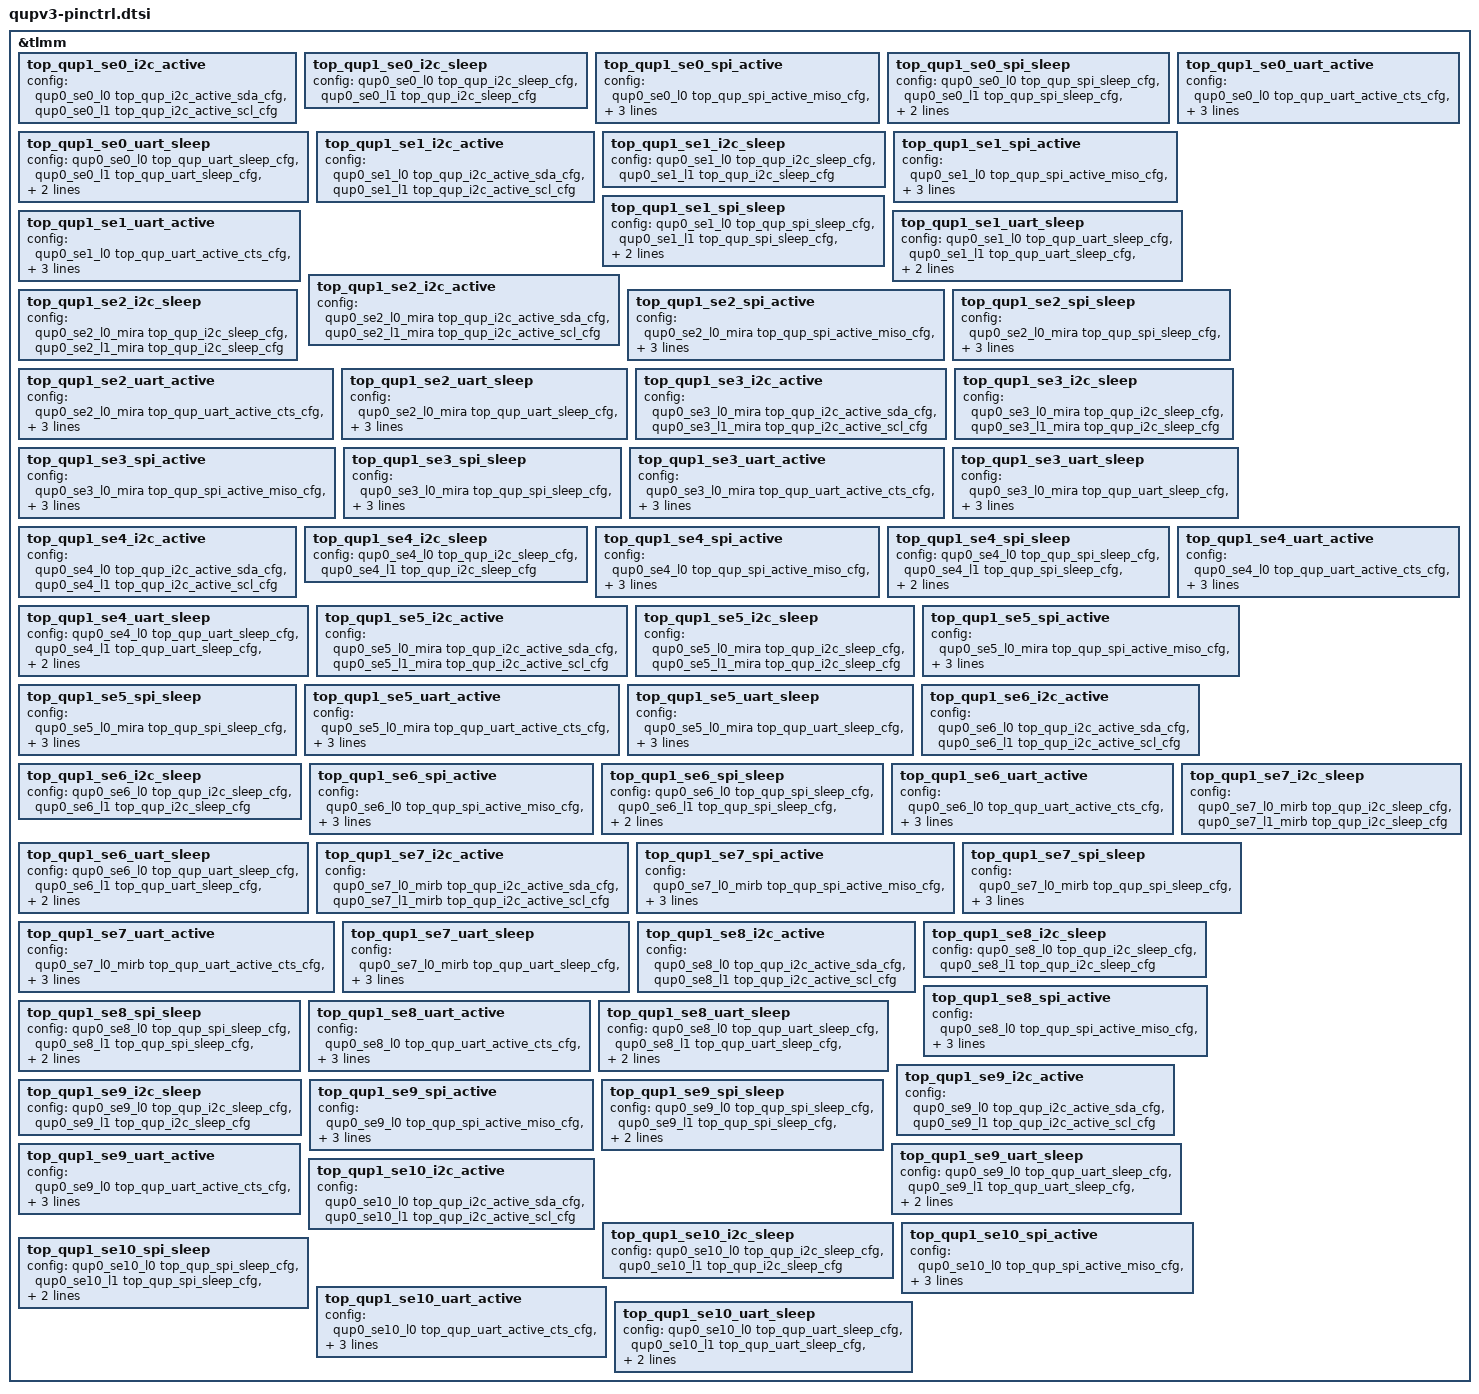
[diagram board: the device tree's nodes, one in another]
/**

This is the settings file for AspenA Top Qup pin control DTSI

Copyright (c) Qualcomm Technologies, Inc.
All Rights Reserved.
Confidential and Proprietary - Qualcomm Technologies, Inc.
*/
/*
===============================================================================
 
                               Edit History
 
$Header:
 
when       who     what, where, why
--------   ---     ------------------------------------------------------------
01/17/25           Initial revision
 
*/

#include "gpio-dt.h"

#define top_qup_spi_sleep_cfg             GPIO_CFG_BUSES(GPIO_INPUT,GPIO_KEEPER,GPIO_DRIVE_STRENGTH(200),0)

#define top_qup_spi_active_miso_cfg       GPIO_CFG_BUSES(GPIO_INPUT,GPIO_NO_PULL,GPIO_DRIVE_STRENGTH(600),0)
#define top_qup_spi_active_mosi_cfg       GPIO_CFG_BUSES(GPIO_OUTPUT,GPIO_NO_PULL,GPIO_DRIVE_STRENGTH(600),0)
#define top_qup_spi_active_clk_cfg        GPIO_CFG_BUSES(GPIO_OUTPUT,GPIO_NO_PULL,GPIO_DRIVE_STRENGTH(600),0)
#define top_qup_spi_active_cs_cfg         GPIO_CFG_BUSES(GPIO_OUTPUT,GPIO_NO_PULL,GPIO_DRIVE_STRENGTH(600),0)

#define top_qup_uart_active_cts_cfg       GPIO_CFG_BUSES(GPIO_INPUT,GPIO_NO_PULL,GPIO_DRIVE_STRENGTH(200),0)
#define top_qup_uart_active_rts_cfg       GPIO_CFG_BUSES(GPIO_OUTPUT,GPIO_NO_PULL,GPIO_DRIVE_STRENGTH(200),0)
#define top_qup_uart_active_tx_cfg        GPIO_CFG_BUSES(GPIO_OUTPUT,GPIO_NO_PULL,GPIO_DRIVE_STRENGTH(200),0)
#define top_qup_uart_active_rx_cfg        GPIO_CFG_BUSES(GPIO_INPUT,GPIO_NO_PULL,GPIO_DRIVE_STRENGTH(200),0)
#define top_qup_uart_sleep_cfg            GPIO_CFG_BUSES(GPIO_INPUT,GPIO_PULL_DOWN,GPIO_DRIVE_STRENGTH(200),0)

#define top_qup_i2c_active_sda_cfg        GPIO_CFG_BUSES(GPIO_OUTPUT,GPIO_PULL_UP,GPIO_DRIVE_STRENGTH(200),GPIO_STRONG_PULL)
#define top_qup_i2c_active_scl_cfg        GPIO_CFG_BUSES(GPIO_OUTPUT,GPIO_PULL_UP,GPIO_DRIVE_STRENGTH(200),GPIO_STRONG_PULL)
#define top_qup_i2c_sleep_cfg             GPIO_CFG_BUSES(GPIO_INPUT,GPIO_NO_PULL,GPIO_DRIVE_STRENGTH(200),GPIO_STRONG_PULL)


#define top_qup_i3c_active_sda_cfg        GPIO_CFG_BUSES(GPIO_OUTPUT,GPIO_PULL_UP,GPIO_DRIVE_STRENGTH(200),0)
#define top_qup_i3c_active_scl_cfg        GPIO_CFG_BUSES(GPIO_OUTPUT,GPIO_PULL_UP,GPIO_DRIVE_STRENGTH(200),0)
#define top_qup_i3c_sleep_cfg             GPIO_CFG_BUSES(GPIO_INPUT,GPIO_KEEPER,GPIO_DRIVE_STRENGTH(200),0)

&tlmm{
    /*top_qup1_se0_pinctrl*/
    top_qup1_se0_i2c_active: top_qup1_se0_i2c_active{
        config = <&qup0_se0_l0 top_qup_i2c_active_sda_cfg>,
                 <&qup0_se0_l1 top_qup_i2c_active_scl_cfg>;
    };

    top_qup1_se0_i2c_sleep: top_qup1_se0_i2c_sleep{
        config = <&qup0_se0_l0 top_qup_i2c_sleep_cfg>,
                 <&qup0_se0_l1 top_qup_i2c_sleep_cfg>;
    };

    top_qup1_se0_spi_active: top_qup1_se0_spi_active{
        config = <&qup0_se0_l0 top_qup_spi_active_miso_cfg>,
                 <&qup0_se0_l1 top_qup_spi_active_mosi_cfg>,
                 <&qup0_se0_l2 top_qup_spi_active_clk_cfg>,
                 <&qup0_se0_l3 top_qup_spi_active_cs_cfg>;
    };

    top_qup1_se0_spi_sleep: top_qup1_se0_spi_sleep{
        config = <&qup0_se0_l0 top_qup_spi_sleep_cfg>,
                 <&qup0_se0_l1 top_qup_spi_sleep_cfg>,
                 <&qup0_se0_l2 top_qup_spi_sleep_cfg>,
                 <&qup0_se0_l3 top_qup_spi_sleep_cfg>;
    };

    top_qup1_se0_uart_active: top_qup1_se0_uart_active{
        config = <&qup0_se0_l0 top_qup_uart_active_cts_cfg>,
                 <&qup0_se0_l1 top_qup_uart_active_rts_cfg>,
                 <&qup0_se0_l2 top_qup_uart_active_tx_cfg>,
                 <&qup0_se0_l3 top_qup_uart_active_rx_cfg>;
    };

    top_qup1_se0_uart_sleep: top_qup1_se0_uart_sleep{
        config = <&qup0_se0_l0 top_qup_uart_sleep_cfg>,
                 <&qup0_se0_l1 top_qup_uart_sleep_cfg>,
                 <&qup0_se0_l2 top_qup_uart_sleep_cfg>,
                 <&qup0_se0_l3 top_qup_uart_sleep_cfg>;
    };

    /*top_qup1_se1_pinctrl*/
    top_qup1_se1_i2c_active: top_qup1_se1_i2c_active{
        config = <&qup0_se1_l0 top_qup_i2c_active_sda_cfg>,
                 <&qup0_se1_l1 top_qup_i2c_active_scl_cfg>;
    };

    top_qup1_se1_i2c_sleep: top_qup1_se1_i2c_sleep{
        config = <&qup0_se1_l0 top_qup_i2c_sleep_cfg>,
                 <&qup0_se1_l1 top_qup_i2c_sleep_cfg>;
    };

    top_qup1_se1_spi_active: top_qup1_se1_spi_active{
        config = <&qup0_se1_l0 top_qup_spi_active_miso_cfg>,
                 <&qup0_se1_l1 top_qup_spi_active_mosi_cfg>,
                 <&qup0_se1_l2 top_qup_spi_active_clk_cfg>,
                 <&qup0_se1_l3 top_qup_spi_active_cs_cfg>;
    };

    top_qup1_se1_spi_sleep: top_qup1_se1_spi_sleep{
        config = <&qup0_se1_l0 top_qup_spi_sleep_cfg>,
                 <&qup0_se1_l1 top_qup_spi_sleep_cfg>,
                 <&qup0_se1_l2 top_qup_spi_sleep_cfg>,
                 <&qup0_se1_l3 top_qup_spi_sleep_cfg>;
    };

    top_qup1_se1_uart_active: top_qup1_se1_uart_active{
        config = <&qup0_se1_l0 top_qup_uart_active_cts_cfg>,
                 <&qup0_se1_l1 top_qup_uart_active_rts_cfg>,
                 <&qup0_se1_l2 top_qup_uart_active_tx_cfg>,
                 <&qup0_se1_l3 top_qup_uart_active_rx_cfg>;
    };

    top_qup1_se1_uart_sleep: top_qup1_se1_uart_sleep{
        config = <&qup0_se1_l0 top_qup_uart_sleep_cfg>,
                 <&qup0_se1_l1 top_qup_uart_sleep_cfg>,
                 <&qup0_se1_l2 top_qup_uart_sleep_cfg>,
                 <&qup0_se1_l3 top_qup_uart_sleep_cfg>;
    };

    /*top_qup1_se2_pinctrl*/
    top_qup1_se2_i2c_active: top_qup1_se2_i2c_active{
        config = <&qup0_se2_l0_mira top_qup_i2c_active_sda_cfg>,
                 <&qup0_se2_l1_mira top_qup_i2c_active_scl_cfg>;
    };

    top_qup1_se2_i2c_sleep: top_qup1_se2_i2c_sleep{
        config = <&qup0_se2_l0_mira top_qup_i2c_sleep_cfg>,
                 <&qup0_se2_l1_mira top_qup_i2c_sleep_cfg>;
    };

    top_qup1_se2_spi_active: top_qup1_se2_spi_active{
        config = <&qup0_se2_l0_mira top_qup_spi_active_miso_cfg>,
                 <&qup0_se2_l1_mira top_qup_spi_active_mosi_cfg>,
                 <&qup0_se2_l2_mira top_qup_spi_active_clk_cfg>,
                 <&qup0_se2_l3_mira top_qup_spi_active_cs_cfg>;
    };

    top_qup1_se2_spi_sleep: top_qup1_se2_spi_sleep{
        config = <&qup0_se2_l0_mira top_qup_spi_sleep_cfg>,
                 <&qup0_se2_l1_mira top_qup_spi_sleep_cfg>,
                 <&qup0_se2_l2_mira top_qup_spi_sleep_cfg>,
                 <&qup0_se2_l3_mira top_qup_spi_sleep_cfg>;
    };

    top_qup1_se2_uart_active: top_qup1_se2_uart_active{
        config = <&qup0_se2_l0_mira top_qup_uart_active_cts_cfg>,
                 <&qup0_se2_l1_mira top_qup_uart_active_rts_cfg>,
                 <&qup0_se2_l2_mira top_qup_uart_active_tx_cfg>,
                 <&qup0_se2_l3_mira top_qup_uart_active_rx_cfg>;
    };

    top_qup1_se2_uart_sleep: top_qup1_se2_uart_sleep{
        config = <&qup0_se2_l0_mira top_qup_uart_sleep_cfg>,
                 <&qup0_se2_l1_mira top_qup_uart_sleep_cfg>,
                 <&qup0_se2_l2_mira top_qup_uart_sleep_cfg>,
                 <&qup0_se2_l3_mira top_qup_uart_sleep_cfg>;
    };

    /*top_qup1_se3_pinctrl*/
    top_qup1_se3_i2c_active: top_qup1_se3_i2c_active{
        config = <&qup0_se3_l0_mira top_qup_i2c_active_sda_cfg>,
                 <&qup0_se3_l1_mira top_qup_i2c_active_scl_cfg>;
    };

    top_qup1_se3_i2c_sleep: top_qup1_se3_i2c_sleep{
        config = <&qup0_se3_l0_mira top_qup_i2c_sleep_cfg>,
                 <&qup0_se3_l1_mira top_qup_i2c_sleep_cfg>;
    };

    top_qup1_se3_spi_active: top_qup1_se3_spi_active{
        config = <&qup0_se3_l0_mira top_qup_spi_active_miso_cfg>,
                 <&qup0_se3_l1_mira top_qup_spi_active_mosi_cfg>,
                 <&qup0_se3_l2_mira top_qup_spi_active_clk_cfg>,
                 <&qup0_se3_l3_mira top_qup_spi_active_cs_cfg>;
    };

    top_qup1_se3_spi_sleep: top_qup1_se3_spi_sleep{
        config = <&qup0_se3_l0_mira top_qup_spi_sleep_cfg>,
                 <&qup0_se3_l1_mira top_qup_spi_sleep_cfg>,
                 <&qup0_se3_l2_mira top_qup_spi_sleep_cfg>,
                 <&qup0_se3_l3_mira top_qup_spi_sleep_cfg>;
    };

    top_qup1_se3_uart_active: top_qup1_se3_uart_active{
        config = <&qup0_se3_l0_mira top_qup_uart_active_cts_cfg>,
                 <&qup0_se3_l1_mira top_qup_uart_active_rts_cfg>,
                 <&qup0_se3_l2_mira top_qup_uart_active_tx_cfg>,
                 <&qup0_se3_l3_mira top_qup_uart_active_rx_cfg>;
    };

    top_qup1_se3_uart_sleep: top_qup1_se3_uart_sleep{
        config = <&qup0_se3_l0_mira top_qup_uart_sleep_cfg>,
                 <&qup0_se3_l1_mira top_qup_uart_sleep_cfg>,
                 <&qup0_se3_l2_mira top_qup_uart_sleep_cfg>,
                 <&qup0_se3_l3_mira top_qup_uart_sleep_cfg>;
    };

    /*top_qup1_se4_pinctrl*/
    top_qup1_se4_i2c_active: top_qup1_se4_i2c_active{
        config = <&qup0_se4_l0 top_qup_i2c_active_sda_cfg>,
                 <&qup0_se4_l1 top_qup_i2c_active_scl_cfg>;
    };

    top_qup1_se4_i2c_sleep: top_qup1_se4_i2c_sleep{
        config = <&qup0_se4_l0 top_qup_i2c_sleep_cfg>,
                 <&qup0_se4_l1 top_qup_i2c_sleep_cfg>;
    };

    top_qup1_se4_spi_active: top_qup1_se4_spi_active{
        config = <&qup0_se4_l0 top_qup_spi_active_miso_cfg>,
                 <&qup0_se4_l1 top_qup_spi_active_mosi_cfg>,
                 <&qup0_se4_l2 top_qup_spi_active_clk_cfg>,
                 <&qup0_se4_l3 top_qup_spi_active_cs_cfg>;
    };

    top_qup1_se4_spi_sleep: top_qup1_se4_spi_sleep{
        config = <&qup0_se4_l0 top_qup_spi_sleep_cfg>,
                 <&qup0_se4_l1 top_qup_spi_sleep_cfg>,
                 <&qup0_se4_l2 top_qup_spi_sleep_cfg>,
                 <&qup0_se4_l3 top_qup_spi_sleep_cfg>;
    };

    top_qup1_se4_uart_active: top_qup1_se4_uart_active{
        config = <&qup0_se4_l0 top_qup_uart_active_cts_cfg>,
                 <&qup0_se4_l1 top_qup_uart_active_rts_cfg>,
                 <&qup0_se4_l2 top_qup_uart_active_tx_cfg>,
                 <&qup0_se4_l3 top_qup_uart_active_rx_cfg>;
    };

    top_qup1_se4_uart_sleep: top_qup1_se4_uart_sleep{
        config = <&qup0_se4_l0 top_qup_uart_sleep_cfg>,
                 <&qup0_se4_l1 top_qup_uart_sleep_cfg>,
                 <&qup0_se4_l2 top_qup_uart_sleep_cfg>,
                 <&qup0_se4_l3 top_qup_uart_sleep_cfg>;
    };

    /*top_qup1_se5_pinctrl*/
    top_qup1_se5_i2c_active: top_qup1_se5_i2c_active{
        config = <&qup0_se5_l0_mira top_qup_i2c_active_sda_cfg>,
                 <&qup0_se5_l1_mira top_qup_i2c_active_scl_cfg>;
    };

    top_qup1_se5_i2c_sleep: top_qup1_se5_i2c_sleep{
        config = <&qup0_se5_l0_mira top_qup_i2c_sleep_cfg>,
                 <&qup0_se5_l1_mira top_qup_i2c_sleep_cfg>;
    };

    top_qup1_se5_spi_active: top_qup1_se5_spi_active{
        config = <&qup0_se5_l0_mira top_qup_spi_active_miso_cfg>,
                 <&qup0_se5_l1_mira top_qup_spi_active_mosi_cfg>,
                 <&qup0_se5_l2_mira top_qup_spi_active_clk_cfg>,
                 <&qup0_se5_l3_mira top_qup_spi_active_cs_cfg>;
    };

    top_qup1_se5_spi_sleep: top_qup1_se5_spi_sleep{
        config = <&qup0_se5_l0_mira top_qup_spi_sleep_cfg>,
                 <&qup0_se5_l1_mira top_qup_spi_sleep_cfg>,
                 <&qup0_se5_l2_mira top_qup_spi_sleep_cfg>,
                 <&qup0_se5_l3_mira top_qup_spi_sleep_cfg>;
    };

    top_qup1_se5_uart_active: top_qup1_se5_uart_active{
        config = <&qup0_se5_l0_mira top_qup_uart_active_cts_cfg>,
                 <&qup0_se5_l1_mira top_qup_uart_active_rts_cfg>,
                 <&qup0_se5_l2_mira top_qup_uart_active_tx_cfg>,
                 <&qup0_se5_l3_mira top_qup_uart_active_rx_cfg>;
    };

    top_qup1_se5_uart_sleep: top_qup1_se5_uart_sleep{
        config = <&qup0_se5_l0_mira top_qup_uart_sleep_cfg>,
                 <&qup0_se5_l1_mira top_qup_uart_sleep_cfg>,
                 <&qup0_se5_l2_mira top_qup_uart_sleep_cfg>,
                 <&qup0_se5_l3_mira top_qup_uart_sleep_cfg>;
    };

    /*top_qup1_se6_pinctrl*/
    top_qup1_se6_i2c_active: top_qup1_se6_i2c_active{
        config = <&qup0_se6_l0 top_qup_i2c_active_sda_cfg>,
                 <&qup0_se6_l1 top_qup_i2c_active_scl_cfg>;
    };

    top_qup1_se6_i2c_sleep: top_qup1_se6_i2c_sleep{
        config = <&qup0_se6_l0 top_qup_i2c_sleep_cfg>,
                 <&qup0_se6_l1 top_qup_i2c_sleep_cfg>;
    };

    top_qup1_se6_spi_active: top_qup1_se6_spi_active{
        config = <&qup0_se6_l0 top_qup_spi_active_miso_cfg>,
                 <&qup0_se6_l1 top_qup_spi_active_mosi_cfg>,
                 <&qup0_se6_l2 top_qup_spi_active_clk_cfg>,
                 <&qup0_se6_l3 top_qup_spi_active_cs_cfg>;
    };

    top_qup1_se6_spi_sleep: top_qup1_se6_spi_sleep{
        config = <&qup0_se6_l0 top_qup_spi_sleep_cfg>,
                 <&qup0_se6_l1 top_qup_spi_sleep_cfg>,
                 <&qup0_se6_l2 top_qup_spi_sleep_cfg>,
                 <&qup0_se6_l3 top_qup_spi_sleep_cfg>;
    };

    top_qup1_se6_uart_active: top_qup1_se6_uart_active{
        config = <&qup0_se6_l0 top_qup_uart_active_cts_cfg>,
                 <&qup0_se6_l1 top_qup_uart_active_rts_cfg>,
                 <&qup0_se6_l2 top_qup_uart_active_tx_cfg>,
                 <&qup0_se6_l3 top_qup_uart_active_rx_cfg>;
    };

    top_qup1_se6_uart_sleep: top_qup1_se6_uart_sleep{
        config = <&qup0_se6_l0 top_qup_uart_sleep_cfg>,
                 <&qup0_se6_l1 top_qup_uart_sleep_cfg>,
                 <&qup0_se6_l2 top_qup_uart_sleep_cfg>,
                 <&qup0_se6_l3 top_qup_uart_sleep_cfg>;
    };

    /*top_qup1_se7_pinctrl*/
    top_qup1_se7_i2c_active: top_qup1_se7_i2c_active{
        config = <&qup0_se7_l0_mirb top_qup_i2c_active_sda_cfg>,
                 <&qup0_se7_l1_mirb top_qup_i2c_active_scl_cfg>;
    };

    top_qup1_se7_i2c_sleep: top_qup1_se7_i2c_sleep{
        config = <&qup0_se7_l0_mirb top_qup_i2c_sleep_cfg>,
                 <&qup0_se7_l1_mirb top_qup_i2c_sleep_cfg>;
    };

    top_qup1_se7_spi_active: top_qup1_se7_spi_active{
        config = <&qup0_se7_l0_mirb top_qup_spi_active_miso_cfg>,
                 <&qup0_se7_l1_mirb top_qup_spi_active_mosi_cfg>,
                 <&qup0_se7_l2_mirb top_qup_spi_active_clk_cfg>,
                 <&qup0_se7_l3_mirb top_qup_spi_active_cs_cfg>;
    };

    top_qup1_se7_spi_sleep: top_qup1_se7_spi_sleep{
        config = <&qup0_se7_l0_mirb top_qup_spi_sleep_cfg>,
                 <&qup0_se7_l1_mirb top_qup_spi_sleep_cfg>,
                 <&qup0_se7_l2_mirb top_qup_spi_sleep_cfg>,
                 <&qup0_se7_l3_mirb top_qup_spi_sleep_cfg>;
    };

    top_qup1_se7_uart_active: top_qup1_se7_uart_active{
        config = <&qup0_se7_l0_mirb top_qup_uart_active_cts_cfg>,
                 <&qup0_se7_l1_mirb top_qup_uart_active_rts_cfg>,
                 <&qup0_se7_l2_mirb top_qup_uart_active_tx_cfg>,
                 <&qup0_se7_l3_mirb top_qup_uart_active_rx_cfg>;
    };

    top_qup1_se7_uart_sleep: top_qup1_se7_uart_sleep{
        config = <&qup0_se7_l0_mirb top_qup_uart_sleep_cfg>,
                 <&qup0_se7_l1_mirb top_qup_uart_sleep_cfg>,
                 <&qup0_se7_l2_mirb top_qup_uart_sleep_cfg>,
                 <&qup0_se7_l3_mirb top_qup_uart_sleep_cfg>;
    };

    /*top_qup1_se8_pinctrl*/
    top_qup1_se8_i2c_active: top_qup1_se8_i2c_active{
        config = <&qup0_se8_l0 top_qup_i2c_active_sda_cfg>,
                 <&qup0_se8_l1 top_qup_i2c_active_scl_cfg>;
    };

    top_qup1_se8_i2c_sleep: top_qup1_se8_i2c_sleep{
        config = <&qup0_se8_l0 top_qup_i2c_sleep_cfg>,
                 <&qup0_se8_l1 top_qup_i2c_sleep_cfg>;
    };

    top_qup1_se8_spi_active: top_qup1_se8_spi_active{
        config = <&qup0_se8_l0 top_qup_spi_active_miso_cfg>,
                 <&qup0_se8_l1 top_qup_spi_active_mosi_cfg>,
                 <&qup0_se8_l2 top_qup_spi_active_clk_cfg>,
                 <&qup0_se8_l3 top_qup_spi_active_cs_cfg>;
    };

    top_qup1_se8_spi_sleep: top_qup1_se8_spi_sleep{
        config = <&qup0_se8_l0 top_qup_spi_sleep_cfg>,
                 <&qup0_se8_l1 top_qup_spi_sleep_cfg>,
                 <&qup0_se8_l2 top_qup_spi_sleep_cfg>,
                 <&qup0_se8_l3 top_qup_spi_sleep_cfg>;
    };

    top_qup1_se8_uart_active: top_qup1_se8_uart_active{
        config = <&qup0_se8_l0 top_qup_uart_active_cts_cfg>,
                 <&qup0_se8_l1 top_qup_uart_active_rts_cfg>,
                 <&qup0_se8_l2 top_qup_uart_active_tx_cfg>,
                 <&qup0_se8_l3 top_qup_uart_active_rx_cfg>;
    };

    top_qup1_se8_uart_sleep: top_qup1_se8_uart_sleep{
        config = <&qup0_se8_l0 top_qup_uart_sleep_cfg>,
                 <&qup0_se8_l1 top_qup_uart_sleep_cfg>,
                 <&qup0_se8_l2 top_qup_uart_sleep_cfg>,
                 <&qup0_se8_l3 top_qup_uart_sleep_cfg>;
    };

    /*top_qup1_se9_pinctrl*/
    top_qup1_se9_i2c_active: top_qup1_se9_i2c_active{
        config = <&qup0_se9_l0 top_qup_i2c_active_sda_cfg>,
                 <&qup0_se9_l1 top_qup_i2c_active_scl_cfg>;
    };

    top_qup1_se9_i2c_sleep: top_qup1_se9_i2c_sleep{
        config = <&qup0_se9_l0 top_qup_i2c_sleep_cfg>,
                 <&qup0_se9_l1 top_qup_i2c_sleep_cfg>;
    };

    top_qup1_se9_spi_active: top_qup1_se9_spi_active{
        config = <&qup0_se9_l0 top_qup_spi_active_miso_cfg>,
                 <&qup0_se9_l1 top_qup_spi_active_mosi_cfg>,
                 <&qup0_se9_l2 top_qup_spi_active_clk_cfg>,
                 <&qup0_se9_l3 top_qup_spi_active_cs_cfg>;
    };

    top_qup1_se9_spi_sleep: top_qup1_se9_spi_sleep{
        config = <&qup0_se9_l0 top_qup_spi_sleep_cfg>,
                 <&qup0_se9_l1 top_qup_spi_sleep_cfg>,
                 <&qup0_se9_l2 top_qup_spi_sleep_cfg>,
                 <&qup0_se9_l3 top_qup_spi_sleep_cfg>;
    };

    top_qup1_se9_uart_active: top_qup1_se9_uart_active{
        config = <&qup0_se9_l0 top_qup_uart_active_cts_cfg>,
                 <&qup0_se9_l1 top_qup_uart_active_rts_cfg>,
                 <&qup0_se9_l2 top_qup_uart_active_tx_cfg>,
                 <&qup0_se9_l3 top_qup_uart_active_rx_cfg>;
    };

    top_qup1_se9_uart_sleep: top_qup1_se9_uart_sleep{
        config = <&qup0_se9_l0 top_qup_uart_sleep_cfg>,
                 <&qup0_se9_l1 top_qup_uart_sleep_cfg>,
                 <&qup0_se9_l2 top_qup_uart_sleep_cfg>,
                 <&qup0_se9_l3 top_qup_uart_sleep_cfg>;
    };

    /*top_qup1_se10_pinctrl*/
    top_qup1_se10_i2c_active: top_qup1_se10_i2c_active{
        config = <&qup0_se10_l0 top_qup_i2c_active_sda_cfg>,
                 <&qup0_se10_l1 top_qup_i2c_active_scl_cfg>;
    };

    top_qup1_se10_i2c_sleep: top_qup1_se10_i2c_sleep{
        config = <&qup0_se10_l0 top_qup_i2c_sleep_cfg>,
                 <&qup0_se10_l1 top_qup_i2c_sleep_cfg>;
    };

    top_qup1_se10_spi_active: top_qup1_se10_spi_active{
        config = <&qup0_se10_l0 top_qup_spi_active_miso_cfg>,
                 <&qup0_se10_l1 top_qup_spi_active_mosi_cfg>,
                 <&qup0_se10_l2 top_qup_spi_active_clk_cfg>,
                 <&qup0_se10_l3 top_qup_spi_active_cs_cfg>;
    };

    top_qup1_se10_spi_sleep: top_qup1_se10_spi_sleep{
        config = <&qup0_se10_l0 top_qup_spi_sleep_cfg>,
                 <&qup0_se10_l1 top_qup_spi_sleep_cfg>,
                 <&qup0_se10_l2 top_qup_spi_sleep_cfg>,
                 <&qup0_se10_l3 top_qup_spi_sleep_cfg>;
    };

    top_qup1_se10_uart_active: top_qup1_se10_uart_active{
        config = <&qup0_se10_l0 top_qup_uart_active_cts_cfg>,
                 <&qup0_se10_l1 top_qup_uart_active_rts_cfg>,
                 <&qup0_se10_l2 top_qup_uart_active_tx_cfg>,
                 <&qup0_se10_l3 top_qup_uart_active_rx_cfg>;
    };

    top_qup1_se10_uart_sleep: top_qup1_se10_uart_sleep{
        config = <&qup0_se10_l0 top_qup_uart_sleep_cfg>,
                 <&qup0_se10_l1 top_qup_uart_sleep_cfg>,
                 <&qup0_se10_l2 top_qup_uart_sleep_cfg>,
                 <&qup0_se10_l3 top_qup_uart_sleep_cfg>;
    };

};
